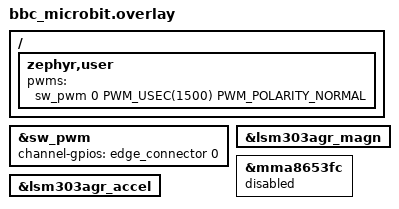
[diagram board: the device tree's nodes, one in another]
/*
 * Copyright (c) 2024 Takayuki Goto <tkg.develop@gmail.com>
 *
 * SPDX-License-Identifier: Apache-2.0
 */

/ {
	zephyr,user {
		/* period cell corresponds to initial period */
		pwms = <&sw_pwm 0 PWM_USEC(1500) PWM_POLARITY_NORMAL>;
	};
};

&sw_pwm {
	status = "okay";
	channel-gpios = <&edge_connector 0 GPIO_ACTIVE_HIGH>;
};

&lsm303agr_magn {
    status = "okay";
};

&mma8653fc {
    status = "disabled";
};

&lsm303agr_accel {
    status = "okay";
};
